VERSION ""

NS_ :

BS_:

BU_: Some_Node

BO_ 3221225472 VECTOR__INDEPENDENT_SIG_MSG: 0 Vector__XXX
 SG_ Test_u16_little : 0|16@1+ (1,0) [0|0] "" Vector__XXX

BO_ 2147487777 Rx_Message_float: 8 Vector__XXX
 SG_ Rx_f32_big : 39|32@0- (1,0) [0|0] ""  Some_Node
 SG_ Rx_f32_little : 0|32@1- (1,0) [0|0] ""  Some_Node

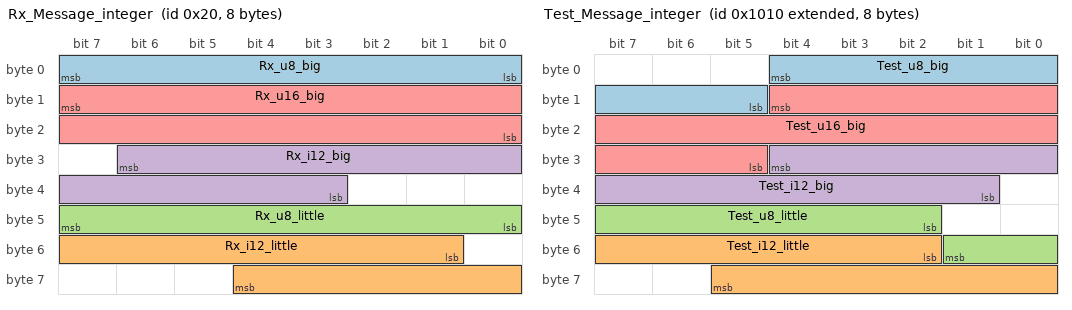
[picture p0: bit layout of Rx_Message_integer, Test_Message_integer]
BO_ 32 Rx_Message_integer: 8 Vector__XXX
 SG_ Rx_u8_big : 7|8@0+ (1,0) [0|0] ""  Some_Node
 SG_ Rx_i12_little : 49|12@1- (1,0) [0|0] ""  Some_Node
 SG_ Rx_u8_little : 40|8@1+ (1,0) [0|0] ""  Some_Node
 SG_ Rx_i12_big : 30|12@0- (1,0) [0|0] ""  Some_Node
 SG_ Rx_u16_big : 15|16@0+ (1,0) [0|0] ""  Some_Node

BO_ 17 Test_Message_float: 8 Some_Node
 SG_ Test_f32_big : 39|32@0- (1,0) [0|0] "" Vector__XXX
 SG_ Test_f32_little : 0|32@1- (1,0) [0|0] "" Vector__XXX

BO_ 2147487760 Test_Message_integer: 8 Some_Node
 SG_ Test_u8_big : 4|8@0+ (1,0) [0|0] "" Vector__XXX
 SG_ Test_i12_little : 50|12@1- (1,0) [0|0] "" Vector__XXX
 SG_ Test_u8_little : 42|8@1+ (1,0) [0|0] "" Vector__XXX
 SG_ Test_i12_big : 28|12@0- (1,0) [0|0] "" Vector__XXX
 SG_ Test_u16_big : 12|16@0+ (1,0) [0|0] "" Vector__XXX

CM_ BO_ 3221225472 "This is a message for not used signals, created by Vector CANdb++ DBC OLE DB Provider.";
BA_DEF_ BO_  "GenMsgCycleTime" INT 0 3600000;
BA_DEF_  "BusType" STRING ;
BA_DEF_DEF_  "GenMsgCycleTime" 0;
BA_DEF_DEF_  "BusType" "CAN";
BA_ "GenMsgCycleTime" BO_ 2147487777 100;
BA_ "GenMsgCycleTime" BO_ 17 100;
SIG_VALTYPE_ 2147487777 Rx_f32_big : 1;
SIG_VALTYPE_ 2147487777 Rx_f32_little : 1;
SIG_VALTYPE_ 17 Test_f32_big : 1;
SIG_VALTYPE_ 17 Test_f32_little : 1;
